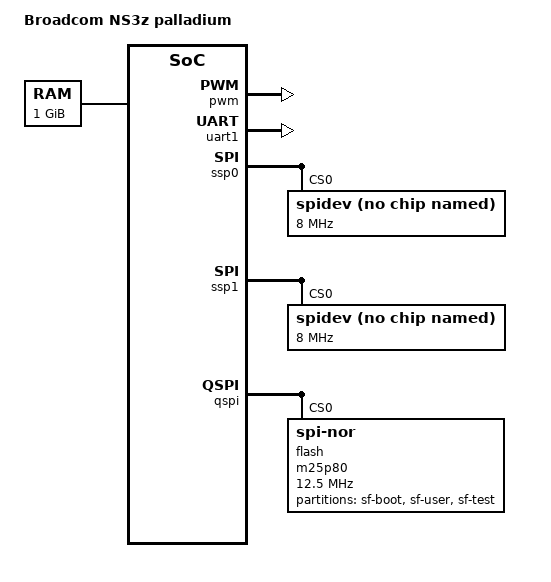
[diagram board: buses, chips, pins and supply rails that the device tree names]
// SPDX-License-Identifier: (GPL-2.0 or BSD-3-Clause)
/*
 *  Copyright(c) 2019 Broadcom
 */

/dts-v1/;

/* HACK: Reserve initrd location
 * The memreserve entry for initrd is supposed
 * to be updated in DTB by bootloader before
 * handing over DTB to Linux kernel.
 */
/memreserve/ 0x81000000 0x00800000;

/* HACK: Reserve bl31 location
 * The memreserve entry for bl31 is supposed to
 * be updated in DTB by bootloader before handing
 * over DTB to Linux kernel. This is so because
 * only firmware (or bootloader) know the correct
 * location of bl31 and bl31 location in DDR can
 * also change in-future.
 */
/memreserve/ 0x8f000000 0x00100000;

#include "../ns3z.dtsi"

/ {
	model = "Broadcom NS3z palladium";

	aliases {
		serial0 = &uart1;
		serial1 = &uart0;
	};

	chosen { /* HACK: hard-code kernel args and initrd location */
		bootargs = "root=/dev/ram rw console=ttyS0,9600n8 \
			    earlycon=uart8250,mmio32,0x68a10000 cma=64M \
			    maxcpus=1";
		linux,initrd-start = <0x0 0x81000000>;
		linux,initrd-end = <0x0 0x81800000>;
	};

	memory: memory@80000000 {
		device_type = "memory";
		reg = <0x00000000 0x80000000 0 0x40000000>;
	};
};

&pwm {
	status = "okay";
};

&uart1 {
	/* Hack: For palladium we force DLL=1 and DLM=0.
	 * To achieve this, we set:
	 * clock-frequency = <desired_baudrate> x 16
	 */
	clock-frequency = <153600>;
	status = "okay";
};

&ssp0 {
	status = "okay";

	spidev@0 {
		compatible = "rohm,dh2228fv";
		spi-max-frequency = <8000000>;
		reg = <0>;
	};
};

&ssp1 {
	status = "okay";

	spidev@0 {
		compatible = "rohm,dh2228fv";
		spi-max-frequency = <8000000>;
		reg = <0>;
	};
};

&qspi {
	pinctrl-names = "default";
	pinctrl-0 = <&qspi_pins>;
	bspi-sel = <0>;
	status = "okay";

	flash: m25p80@0 {
		#address-cells = <1>;
		#size-cells = <1>;
		compatible = "jedec,spi-nor";
		reg = <0x0>;
		spi-max-frequency = <12500000>;
		m25p,fast-read;
		spi-cpol;
		spi-cpha;

		partition@0 {
			label = "sf-boot";		/* 2 MiB */
			reg = <0x00000000 0x00200000>;
		};

		partition@400000 {			/* 1 MiB */
			label = "sf-user";
			reg = <0x00200000 0x00100000>;
		};

		partition@600000 {			/* 1 MiB */
			label = "sf-test";
			reg = <0x00300000 0x00100000>;
		};
	};
};
